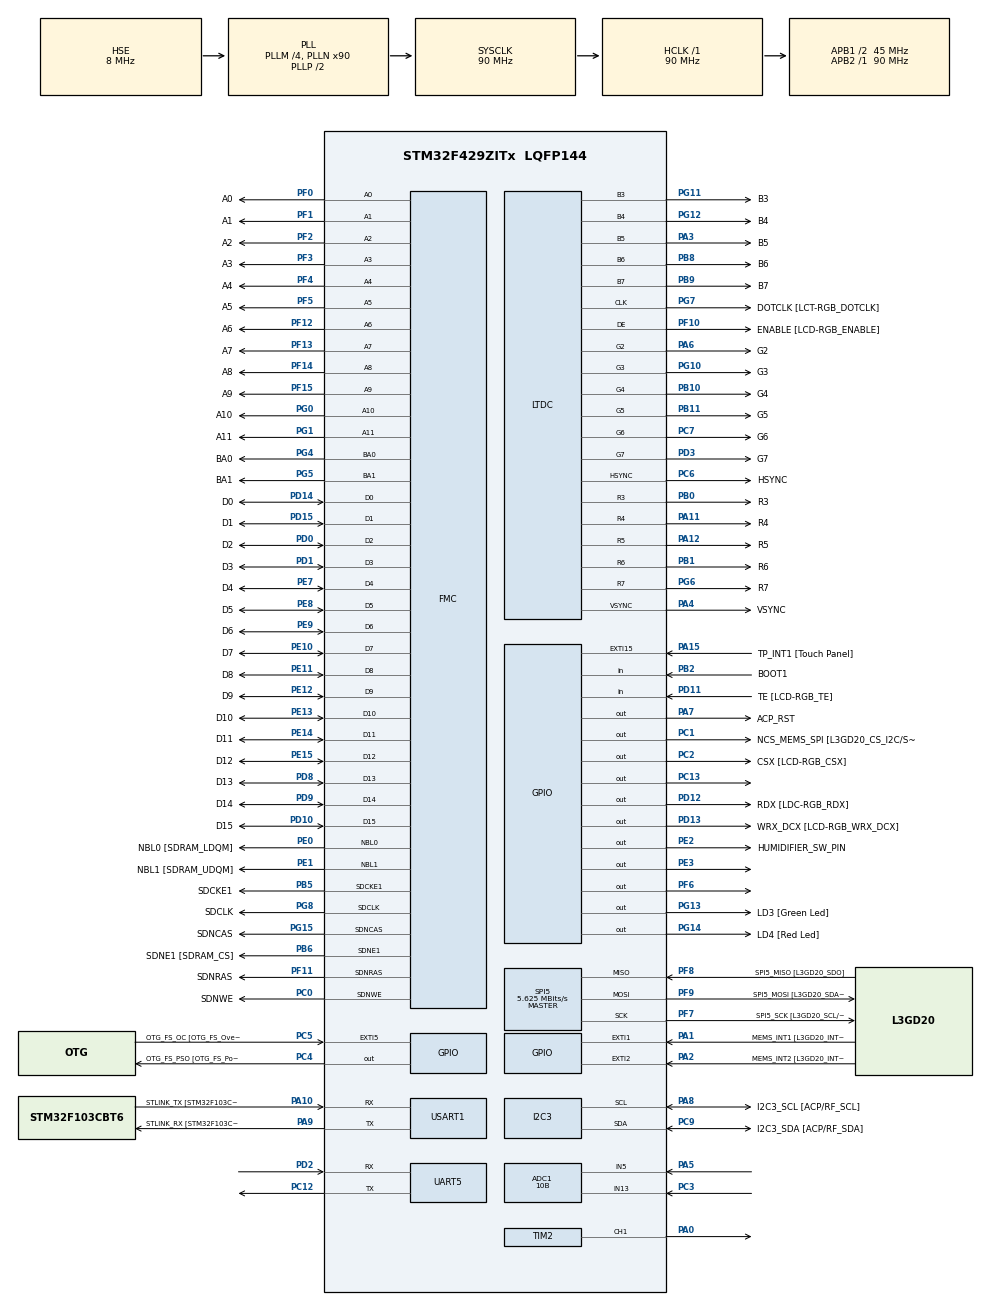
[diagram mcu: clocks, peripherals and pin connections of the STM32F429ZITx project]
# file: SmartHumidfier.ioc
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PF5.GPIO_PuPd=GPIO_NOPULL
FREERTOS.Queues01=envQueue,16,ENV_MSG,0,Dynamic,NULL,NULL
PD12.GPIO_Label=RDX [LDC-RGB_RDX]
FMC.SDClockPeriod2=FMC_SDRAM_CLOCK_PERIOD_2
FMC.SDClockPeriod1=FMC_SDRAM_CLOCK_PERIOD_2
SH.FMC_A0.0=FMC_A0,12b-sda1
PB10.GPIO_PuPd=GPIO_NOPULL
NVIC.TIM6_DAC_IRQn=true\:0\:0\:false\:false\:true\:false\:false\:true
PG8.Signal=FMC_SDCLK
FREERTOS.Events01=eventFlag,Dynamic,NULL
PG0.Signal=FMC_A10
PA3.GPIO_PuPd=GPIO_NOPULL
PE10.GPIO_PuPd=GPIO_NOPULL
PD10.GPIO_PuPd=GPIO_NOPULL
SH.FMC_D5_DA5.0=FMC_D5,sd-16b-d1
PF10.GPIO_PuPd=GPIO_NOPULL
PG10.GPIO_PuPd=GPIO_NOPULL
PA6.GPIO_Mode=GPIO_MODE_AF_PP
SH.FMC_D9_DA9.0=FMC_D9,sd-16b-d1
PB2/BOOT1.GPIO_Mode=GPIO_MODE_INPUT
PG13.GPIO_Mode=GPIO_MODE_OUTPUT_PP
PE13.GPIO_Mode=GPIO_MODE_AF_PP
PF13.GPIO_Mode=GPIO_MODE_AF_PP
PG15.GPIO_Label=SDNCAS
PA4.Mode=RGB565
PF7.Signal=SPI5_SCK
PD13.GPIO_Mode=GPIO_MODE_OUTPUT_PP
NVIC.DMA2D_IRQn=true\:5\:0\:true\:false\:true\:true\:true\:true
SH.FMC_SDNWE.0=FMC_SDNWE,12b-sda1
PA15.GPIO_ModeDefaultEXTI=GPIO_MODE_EVT_RISING
SH.FMC_D11_DA11.0=FMC_D11,sd-16b-d1
PG7.GPIO_Mode=GPIO_MODE_AF_PP
RCC.APB2TimFreq_Value=90000000
PC4.GPIO_Mode=GPIO_MODE_OUTPUT_PP
PB6.Signal=FMC_SDNE1
PC7.Signal=LTDC_G6
PD0.Signal=FMC_D2_DA2
PD8.Signal=FMC_D13_DA13
PE1.Signal=FMC_NBL1
ADC1.ScanConvMode=ENABLE
PF1.GPIO_Label=A1
PC1.GPIO_PuPd=GPIO_NOPULL
PD1.GPIO_Label=D3
FMC.SelfRefreshTime1=4
PF12.GPIO_Label=A6
LTDC.PixelFormat_L0=LTDC_PIXEL_FORMAT_RGB565
PC4.GPIO_Label=OTG_FS_PSO [OTG_FS_PowerSwitchOn]
PB1.GPIO_Speed=GPIO_SPEED_FREQ_LOW
PE9.Signal=FMC_D6_DA6
PD1.GPIO_Speed=GPIO_SPEED_FREQ_VERY_HIGH
SH.FMC_A2.0=FMC_A2,12b-sda1
PB1.GPIO_Label=R6
PG4.GPIO_Label=BA0
PC9.Mode=I2C
PD14.GPIO_PuPd=GPIO_NOPULL
PA8.Signal=I2C3_SCL
SH.FMC_D1_DA1.0=FMC_D1,sd-16b-d1
PF1.GPIO_Speed=GPIO_SPEED_FREQ_VERY_HIGH
PF1.GPIO_Mode=GPIO_MODE_AF_PP
LTDC.HSync=10
PF14.GPIO_PuPd=GPIO_NOPULL
PG0.GPIO_PuPd=GPIO_NOPULL
PE9.GPIO_Mode=GPIO_MODE_AF_PP
Mcu.Package=LQFP144
PB9.Signal=LTDC_B7
TIM2.Prescaler=900-1
PB1.Signal=LTDC_R6
NVIC.TimeBase=TIM6_DAC_IRQn
PD12.Signal=GPIO_Output
NVIC.TimeBaseIP=TIM6
PA10.Signal=USART1_RX
PB9.GPIO_PuPd=GPIO_NOPULL
PE12.GPIO_Label=D9
FMC.WriteRecoveryTime1=3
PE12.GPIO_Speed=GPIO_SPEED_FREQ_VERY_HIGH
PB5.GPIO_Speed=GPIO_SPEED_FREQ_VERY_HIGH
SPI5.CalculateBaudRate=5.625 MBits/s
PE8.GPIO_Speed=GPIO_SPEED_FREQ_VERY_HIGH
PG8.GPIO_Speed=GPIO_SPEED_FREQ_VERY_HIGH
LTDC.VSync=2
PF5.GPIO_Speed=GPIO_SPEED_FREQ_VERY_HIGH
RCC.APB1TimFreq_Value=90000000
FMC.RowCycleDelay2=7
PF10.Mode=RGB565
FMC.RowCycleDelay1=7
PD3.GPIO_PuPd=GPIO_NOPULL
PF9.GPIO_PuPd=GPIO_NOPULL
PA4.GPIO_Label=VSYNC
PA8.GPIO_Speed=GPIO_SPEED_FREQ_LOW
PD15.Signal=FMC_D1_DA1
PG12.Signal=LTDC_B4
PB5.GPIO_Mode=GPIO_MODE_AF_PP
SH.FMC_A4.0=FMC_A4,12b-sda1
FREERTOS.Tasks01=defaultTask,8,4096,StartDefaultTask,Default,NULL,Dynamic,NULL,NULL;lcdTask,24,512,_TouchGFX_Task,Default,NULL,Dynamic,NULL,NULL;eventHandlerTas,40,2048,___eventHandler,Default,NULL,Dynamic,NULL,NULL;event_loop_task,32,512,_eventLoopTask,Default,NULL,Dynamic,NULL,NULL
PF4.GPIO_Mode=GPIO_MODE_AF_PP
PG5.Signal=FMC_A15_BA1
SH.FMC_D10_DA10.0=FMC_D10,sd-16b-d1
PC13.Signal=GPIO_Output
PB6.GPIO_PuPd=GPIO_NOPULL
PD3.Signal=LTDC_G7
PC2.Signal=GPIO_Output
PF5.GPIO_Mode=GPIO_MODE_AF_PP
PG8.GPIO_PuPd=GPIO_NOPULL
PF8.GPIO_Label=SPI5_MISO [L3GD20_SDO]
LTDC.ImageWidth_L0=240
PD10.Signal=FMC_D15_DA15
PA3.Mode=RGB565
PB8.GPIO_Label=B6
PB10.GPIO_Mode=GPIO_MODE_AF_PP
PA8.GPIO_Label=I2C3_SCL [ACP/RF_SCL]
PE8.GPIO_Label=D5
PB1.GPIO_Mode=GPIO_MODE_AF_PP
PC5.GPIO_ModeDefaultEXTI=GPIO_MODE_EVT_RISING
PG10.GPIO_Mode=GPIO_MODE_AF_PP
PA5.Signal=ADCx_IN5
PC12.Mode=Asynchronous
PF10.GPIO_Mode=GPIO_MODE_AF_PP
PE1.GPIO_Label=NBL1 [SDRAM_UDQM]
PF15.GPIO_Speed=GPIO_SPEED_FREQ_VERY_HIGH
PF13.GPIO_PuPd=GPIO_NOPULL
FMC.ReadBurst1=FMC_SDRAM_RBURST_DISABLE
SH.FMC_A6.0=FMC_A6,12b-sda1
PE14.Signal=FMC_D11_DA11
PF12.GPIO_Speed=GPIO_SPEED_FREQ_VERY_HIGH
PG7.GPIO_Label=DOTCLK [LCT-RGB_DOTCLK]
PF4.GPIO_Label=A4
PA1.GPIO_Label=MEMS_INT1 [L3GD20_INT1]
PC9.GPIO_PuPd=GPIO_NOPULL
PC1.GPIO_Speed=GPIO_SPEED_FREQ_LOW
PF13.Signal=FMC_A7
TIM2.Period=65535
PG14.GPIO_PuPd=GPIO_NOPULL
PG1.GPIO_Speed=GPIO_SPEED_FREQ_VERY_HIGH
PC7.GPIO_Label=G6
ADC1.master=1
PB5.GPIO_PuPd=GPIO_NOPULL
ProjectManager.HeapSize=0x200
PB1.Mode=RGB565
PD0.GPIO_PuPd=GPIO_NOPULL
FREERTOS.configUSE_RECURSIVE_MUTEXES=1
PG12.GPIO_Speed=GPIO_SPEED_FREQ_LOW
PD8.GPIO_Speed=GPIO_SPEED_FREQ_VERY_HIGH
NVIC.PriorityGroup=NVIC_PRIORITYGROUP_4
PF0.GPIO_Label=A0
PE15.GPIO_Speed=GPIO_SPEED_FREQ_VERY_HIGH
PE3.Signal=GPIO_Output
PF4.Signal=FMC_A4
PD2.Signal=UART5_RX
PD14.GPIO_Mode=GPIO_MODE_AF_PP
PG5.GPIO_Speed=GPIO_SPEED_FREQ_VERY_HIGH
Mcu.Family=STM32F4
LTDC.BlendingFactor1_L0=LTDC_BLENDING_FACTOR1_CA
PA6.Mode=RGB565
SH.FMC_A8.0=FMC_A8,12b-sda1
FREERTOS.BinarySemaphores01=sensorSem,Dynamic,NULL
TIM2.OCFastMode_PWM-PWM\ Generation1\ CH1=TIM_OCFAST_ENABLE
ADC1.ContinuousConvMode=ENABLE
SH.FMC_D14_DA14.0=FMC_D14,sd-16b-d1
PE11.GPIO_Label=D8
PA7.GPIO_Mode=GPIO_MODE_OUTPUT_PP
PD9.GPIO_Speed=GPIO_SPEED_FREQ_VERY_HIGH
PD0.GPIO_Label=D2
PA11.Mode=RGB565
PF9.GPIO_Speed=GPIO_SPEED_FREQ_LOW
PC2.GPIO_Speed=GPIO_SPEED_FREQ_LOW
SH.FMC_A14_BA0.0=FMC_BA0,FourSdramBanks1
SH.FMC_A11.0=FMC_A11,12b-sda1
PD8.GPIO_PuPd=GPIO_NOPULL
PG5.GPIO_Label=BA1
PG11.Signal=LTDC_B3
PG15.Signal=FMC_SDNCAS
PD13.Signal=GPIO_Output
PA15.GPIO_Label=TP_INT1 [Touch Panel]
PE11.GPIO_PuPd=GPIO_NOPULL
PF11.GPIO_PuPd=GPIO_NOPULL
PB1.GPIO_PuPd=GPIO_NOPULL
ADC1.Resolution=ADC_RESOLUTION_10B
PF13.GPIO_Speed=GPIO_SPEED_FREQ_VERY_HIGH
SH.FMC_NBL1.0=FMC_NBL1,Sd2ByteEnable1
LTDC.WindowX1_L0=240
PG5.GPIO_PuPd=GPIO_NOPULL
RCC.HSE_VALUE=8000000
FREERTOS.configUSE_TIMERS=1
PA4.GPIO_PuPd=GPIO_NOPULL
FMC.ExitSelfRefreshDelay1=7
PF7.GPIO_Mode=GPIO_MODE_AF_PP
PE13.GPIO_PuPd=GPIO_NOPULL
PA4.GPIO_Speed=GPIO_SPEED_FREQ_LOW
FREERTOS.configENABLE_BACKWARD_COMPATIBILITY=1
PG11.GPIO_Speed=GPIO_SPEED_FREQ_LOW
PH1/OSC_OUT.GPIO_Label=PH1-OSC_OUT
PC4.GPIO_Speed=GPIO_SPEED_FREQ_LOW
PA6.GPIO_PuPd=GPIO_NOPULL
PF9.Mode=Full_Duplex_Master
PF7.GPIO_Speed=GPIO_SPEED_FREQ_LOW
PF8.GPIO_PuPd=GPIO_NOPULL
PA14.Mode=Serial_Wire
PB2/BOOT1.GPIO_PuPd=GPIO_NOPULL
PF11.Signal=FMC_SDNRAS
PB5.Mode=SdramChipSelect2_1
PC7.GPIO_Mode=GPIO_MODE_AF_PP
PG7.GPIO_PuPd=GPIO_NOPULL
TIM2.Channel-PWM\ Generation1\ CH1=TIM_CHANNEL_1
PD10.GPIO_Speed=GPIO_SPEED_FREQ_VERY_HIGH
PG4.GPIO_Mode=GPIO_MODE_AF_PP
PD13.GPIO_Label=WRX_DCX [LCD-RGB_WRX_DCX]
PA6.Signal=LTDC_G2
PB0.GPIO_Mode=GPIO_MODE_AF_PP
PG1.GPIO_PuPd=GPIO_NOPULL
PA15.Signal=GPXTI15
PF8.Signal=SPI5_MISO
PG0.GPIO_Label=A10
PB5.GPIO_Label=SDCKE1
PD0.GPIO_Mode=GPIO_MODE_AF_PP
PG14.GPIO_Mode=GPIO_MODE_OUTPUT_PP
PG11.GPIO_Label=B3
PC5.Signal=GPXTI5
PD3.GPIO_Label=G7
PE14.GPIO_Mode=GPIO_MODE_AF_PP
PE7.Signal=FMC_D4_DA4
ADC1.Rank-6\#ChannelRegularConversion=1
PF3.GPIO_Label=A3
PA1.GPIO_ModeDefaultEXTI=GPIO_MODE_EVT_RISING
PE2.GPIO_Label=HUMIDIFIER_SW_PIN
PA12.GPIO_Speed=GPIO_SPEED_FREQ_LOW
STMicroelectronics.X-CUBE-TOUCHGFX.4.16.1.tgfx_vsync=vsync_ltdc
PA3.Signal=LTDC_B5
PE0.GPIO_PuPd=GPIO_NOPULL
PG1.GPIO_Mode=GPIO_MODE_AF_PP
NVIC.LTDC_IRQn=true\:5\:0\:true\:false\:true\:true\:true\:true
SH.ADCx_IN13.0=ADC1_IN13,IN13
LTDC.VFP=4
PD15.GPIO_Label=D1
LTDC.WindowY1_L0=320
PG7.Signal=LTDC_CLK
PA10.Mode=Asynchronous
PC9.GPIO_Label=I2C3_SDA [ACP/RF_SDA]
PF10.GPIO_Speed=GPIO_SPEED_FREQ_LOW
PE14.GPIO_Label=D11
PD9.Signal=FMC_D14_DA14
SPI5.Mode=SPI_MODE_MASTER
PA12.GPIO_Label=R5
PD8.GPIO_Label=D13
PB0.GPIO_Speed=GPIO_SPEED_FREQ_LOW
PG8.GPIO_Label=SDCLK
PA13.Signal=SYS_JTMS-SWDIO
FREERTOS.configUSE_IDLE_HOOK=1
PA9.Mode=Asynchronous
PB2/BOOT1.Signal=GPIO_Input
PF6.Signal=GPIO_Output
PB10.GPIO_Label=G4
PC9.GPIO_Mode=GPIO_MODE_AF_OD
SH.FMC_D13_DA13.0=FMC_D13,sd-16b-d1
PA3.GPIO_Mode=GPIO_MODE_AF_PP
PG0.GPIO_Speed=GPIO_SPEED_FREQ_VERY_HIGH
PB9.Mode=RGB565
PF9.GPIO_Label=SPI5_MOSI [L3GD20_SDA/SDI/SDO]
PD10.GPIO_Label=D15
PA1.Signal=GPXTI1
PA7.GPIO_PuPd=GPIO_NOPULL
PD2.Mode=Asynchronous
PE10.GPIO_Mode=GPIO_MODE_AF_PP
board=STM32F429I-DISC1
PD13.GPIO_Speed=GPIO_SPEED_FREQ_LOW
PG12.Mode=RGB565
PC7.GPIO_Speed=GPIO_SPEED_FREQ_LOW
RCC.VCOOutputFreq_Value=180000000
PA4.GPIO_Mode=GPIO_MODE_AF_PP
PF4.GPIO_Speed=GPIO_SPEED_FREQ_VERY_HIGH
PC1.GPIO_Label=NCS_MEMS_SPI [L3GD20_CS_I2C/SPI]
PE11.GPIO_Mode=GPIO_MODE_AF_PP
SH.FMC_D12_DA12.0=FMC_D12,sd-16b-d1
PF15.GPIO_Label=A9
PE14.GPIO_PuPd=GPIO_NOPULL
PF1.Signal=FMC_A1
ADC1.NbrOfConversion=1
PF8.GPIO_Mode=GPIO_MODE_AF_PP
PE0.Signal=FMC_NBL0
PE7.GPIO_Label=D4
PE12.Signal=FMC_D9_DA9
PE12.GPIO_Mode=GPIO_MODE_AF_PP
RCC.48MHZClocksFreq_Value=60000000
RCC.SYSCLKFreq_VALUE=90000000
PE15.GPIO_PuPd=GPIO_NOPULL
PG4.GPIO_PuPd=GPIO_NOPULL
PD3.GPIO_Mode=GPIO_MODE_AF_PP
RCC.HSI_VALUE=16000000
PA8.GPIO_PuPd=GPIO_NOPULL
PA2.GPIO_ModeDefaultEXTI=GPIO_MODE_EVT_RISING
PH0/OSC_IN.GPIO_Label=PH0-OSC_IN
PF9.GPIO_Mode=GPIO_MODE_AF_PP
RCC.PLLQ=3
RCC.PLLM=4
RCC.PLLN=90
PG0.GPIO_Mode=GPIO_MODE_AF_PP
PB8.GPIO_Speed=GPIO_SPEED_FREQ_LOW
PG14.GPIO_Speed=GPIO_SPEED_FREQ_LOW
VP_CRC_VS_CRC.Mode=CRC_Activate
LTDC.ImageHeight_L0=320
PB0.GPIO_PuPd=GPIO_NOPULL
PA3.GPIO_Label=B5
PA11.GPIO_Speed=GPIO_SPEED_FREQ_LOW
PF15.GPIO_Mode=GPIO_MODE_AF_PP
SH.FMC_D7_DA7.0=FMC_D7,sd-16b-d1
PE15.GPIO_Mode=GPIO_MODE_AF_PP
PD1.GPIO_Mode=GPIO_MODE_AF_PP
PD15.GPIO_Mode=GPIO_MODE_AF_PP
VP_SYS_VS_tim6.Mode=TIM6
PE14.GPIO_Speed=GPIO_SPEED_FREQ_VERY_HIGH
FMC.RCDDelay1=2
PB10.Mode=RGB565
PA8.GPIO_Mode=GPIO_MODE_AF_OD
PG4.Signal=FMC_A14_BA0
ADC1.SamplingTime-6\#ChannelRegularConversion=ADC_SAMPLETIME_15CYCLES
PC12.Signal=UART5_TX
PG6.GPIO_Label=R7
PA14.GPIO_Label=SWCLK
PE8.GPIO_PuPd=GPIO_NOPULL
FMC.LoadToActiveDelay1=2
PC6.GPIO_Label=HSYNC
PA6.GPIO_Label=G2
PB6.GPIO_Label=SDNE1 [SDRAM_CS]
PA3.GPIO_Speed=GPIO_SPEED_FREQ_LOW
PD3.GPIO_Speed=GPIO_SPEED_FREQ_LOW
PG6.Mode=RGB565
PG13.Signal=GPIO_Output
RCC.SYSCLKSource=RCC_SYSCLKSOURCE_PLLCLK
PG15.GPIO_Mode=GPIO_MODE_AF_PP
PB11.GPIO_Speed=GPIO_SPEED_FREQ_LOW
SH.FMC_A15_BA1.0=FMC_BA1,FourSdramBanks1
PD14.GPIO_Speed=GPIO_SPEED_FREQ_VERY_HIGH
PB2/BOOT1.GPIO_Label=BOOT1
PH1/OSC_OUT.Signal=RCC_OSC_OUT
PB6.Mode=SdramChipSelect2_1
PC3.Signal=ADCx_IN13
PA1.GPIO_PuPd=GPIO_NOPULL
PF10.GPIO_Label=ENABLE [LCD-RGB_ENABLE]
PF14.GPIO_Speed=GPIO_SPEED_FREQ_VERY_HIGH
PG6.GPIO_PuPd=GPIO_NOPULL
PF11.GPIO_Mode=GPIO_MODE_AF_PP
STMicroelectronics.X-CUBE-TOUCHGFX.4.16.1.tgfx_display_interface=disp_ltdc
PD11.GPIO_Mode=GPIO_MODE_INPUT
PE2.Signal=GPIO_Output
PF8.Mode=Full_Duplex_Master
PF3.Signal=FMC_A3
PD3.Mode=RGB565
PE10.Signal=FMC_D7_DA7
VP_TIM1_VS_ClockSourceINT.Mode=Internal
STMicroelectronics.X-CUBE-TOUCHGFX.4.16.1.ApplicationCcGraphicsJjApplication=TouchGFXOoGenerator
PF3.GPIO_Speed=GPIO_SPEED_FREQ_VERY_HIGH
PF3.GPIO_PuPd=GPIO_NOPULL
PC6.GPIO_PuPd=GPIO_NOPULL
SH.FMC_A1.0=FMC_A1,12b-sda1
SH.FMC_SDCLK.0=FMC_SDCLK,12b-sda1
PC2.GPIO_Mode=GPIO_MODE_OUTPUT_PP
PG12.GPIO_PuPd=GPIO_NOPULL
PF14.Signal=FMC_A8
VP_DMA2D_VS_DMA2D.Mode=DMA2D_Activate
PA6.GPIO_Speed=GPIO_SPEED_FREQ_LOW
PB11.GPIO_Mode=GPIO_MODE_AF_PP
PA12.GPIO_PuPd=GPIO_NOPULL
PE10.GPIO_Label=D7
PD9.GPIO_PuPd=GPIO_NOPULL
PC6.GPIO_Speed=GPIO_SPEED_FREQ_LOW
SH.FMC_D3_DA3.0=FMC_D3,sd-16b-d1
SPI5.VirtualType=VM_MASTER
PG6.GPIO_Speed=GPIO_SPEED_FREQ_LOW
PE12.GPIO_PuPd=GPIO_NOPULL
PD8.GPIO_Mode=GPIO_MODE_AF_PP
VP_STMicroelectronics.X-CUBE-TOUCHGFX_VS_GraphicsJjApplication_4.16.1.Mode=GraphicsJjApplication
PD9.GPIO_Label=D14
STMicroelectronics.X-CUBE-TOUCHGFX.4.16.1.tgfx_address1=0xD0000000
PE11.GPIO_Speed=GPIO_SPEED_FREQ_VERY_HIGH
PA9.GPIO_Label=STLINK_RX [STM32F103CBT6_PA3]
FREERTOS.configCHECK_FOR_STACK_OVERFLOW=2
PD9.GPIO_Mode=GPIO_MODE_AF_PP
PB8.GPIO_PuPd=GPIO_NOPULL
PC6.Signal=LTDC_HSYNC
PB11.GPIO_Label=G5
PD1.Signal=FMC_D3_DA3
PA11.GPIO_Label=R4
PE1.GPIO_PuPd=GPIO_NOPULL
PF14.GPIO_Label=A8
PD1.GPIO_PuPd=GPIO_NOPULL
UART5.VirtualMode=Asynchronous
PC0.Signal=FMC_SDNWE
RCC.APB1CLKDivider=RCC_HCLK_DIV2
PF13.GPIO_Label=A7
PG13.GPIO_Label=LD3 [Green Led]
PD0.GPIO_Speed=GPIO_SPEED_FREQ_VERY_HIGH
PG10.Signal=LTDC_G3
PE0.GPIO_Speed=GPIO_SPEED_FREQ_VERY_HIGH
PF11.GPIO_Speed=GPIO_SPEED_FREQ_VERY_HIGH
SH.FMC_A3.0=FMC_A3,12b-sda1
FMC.CASLatency1=FMC_SDRAM_CAS_LATENCY_3
PF2.GPIO_Mode=GPIO_MODE_AF_PP
PB11.Mode=RGB565
SH.FMC_D15_DA15.0=FMC_D15,sd-16b-d1
PC6.Mode=RGB565
PA9.Signal=USART1_TX
PC7.GPIO_PuPd=GPIO_NOPULL
PE9.GPIO_Label=D6
PB10.Signal=LTDC_G4
PA7.GPIO_Speed=GPIO_SPEED_FREQ_LOW
PE7.GPIO_Speed=GPIO_SPEED_FREQ_VERY_HIGH
PE15.Signal=FMC_D12_DA12
PG11.GPIO_Mode=GPIO_MODE_AF_PP
PE8.Signal=FMC_D5_DA5
PG5.GPIO_Mode=GPIO_MODE_AF_PP
PC6.GPIO_Mode=GPIO_MODE_AF_PP
ADC1.DMAContinuousRequests=DISABLE
PA13.Mode=Serial_Wire
PG14.GPIO_Label=LD4 [Red Led]
SH.FMC_SDNCAS.0=FMC_SDNCAS,12b-sda1
PG12.GPIO_Mode=GPIO_MODE_AF_PP
PF7.GPIO_PuPd=GPIO_NOPULL
PA4.Signal=LTDC_VSYNC
PB5.Signal=FMC_SDCKE1
PE13.GPIO_Label=D10
FREERTOS.configUSE_COUNTING_SEMAPHORES=1
PE3.GPIO_ModeDefaultOutputPP=GPIO_MODE_OUTPUT_PP
PD11.Signal=GPIO_Input
USART1.VirtualMode=VM_ASYNC
SH.FMC_A5.0=FMC_A5,12b-sda1
PG11.Mode=RGB565
LTDC.Alpha_L0=255
PA11.Signal=LTDC_R4
SH.S_TIM2_CH1_ETR.0=TIM2_CH1,PWM Generation1 CH1
PF9.Signal=SPI5_MOSI
FREERTOS.Timers01=updateSensorTimer,CallbackUpdateSensor,osTimerPeriodic,Default,NULL,Dynamic,NULL
SH.ADCx_IN5.0=ADC1_IN5,IN5
PC9.GPIO_Speed=GPIO_SPEED_FREQ_LOW
PB8.Mode=RGB565
PF12.GPIO_PuPd=GPIO_NOPULL
TIM2.AutoReloadPreload=TIM_AUTORELOAD_PRELOAD_ENABLE
PA8.Mode=I2C
PB6.GPIO_Speed=GPIO_SPEED_FREQ_VERY_HIGH
PG6.GPIO_Mode=GPIO_MODE_AF_PP
PB0.Signal=LTDC_R3
PE0.GPIO_Mode=GPIO_MODE_AF_PP
PC1.Signal=GPIO_Output
PF3.GPIO_Mode=GPIO_MODE_AF_PP
PG10.GPIO_Label=G3
PG15.GPIO_PuPd=GPIO_NOPULL
PA2.GPIO_PuPd=GPIO_NOPULL
PE7.GPIO_PuPd=GPIO_NOPULL
RCC.CortexFreq_Value=90000000
PG6.Signal=LTDC_R7
PB10.GPIO_Speed=GPIO_SPEED_FREQ_LOW
PB6.GPIO_Mode=GPIO_MODE_AF_PP
LTDC.HBP=20
PD15.GPIO_Speed=GPIO_SPEED_FREQ_VERY_HIGH
PF4.GPIO_PuPd=GPIO_NOPULL
SH.FMC_NBL0.0=FMC_NBL0,Sd2ByteEnable1
SH.FMC_D6_DA6.0=FMC_D6,sd-16b-d1
PC0.GPIO_Label=SDNWE
PE9.GPIO_Speed=GPIO_SPEED_FREQ_VERY_HIGH
PA0/WKUP.Signal=S_TIM2_CH1_ETR
PB0.GPIO_Label=R3
PA11.GPIO_PuPd=GPIO_NOPULL
PB11.GPIO_PuPd=GPIO_NOPULL
PB11.Signal=LTDC_G5
PG8.GPIO_Mode=GPIO_MODE_AF_PP
STMicroelectronics.X-CUBE-TOUCHGFX.4.16.1.tgfx_location=By Address
PF2.GPIO_Speed=GPIO_SPEED_FREQ_VERY_HIGH
ProjectManager.StackSize=0x400
VP_FREERTOS_VS_CMSIS_V2.Mode=CMSIS_V2
NVIC.UART5_IRQn=true\:5\:0\:false\:false\:true\:true\:true\:true
PD11.GPIO_PuPd=GPIO_NOPULL
SH.FMC_A7.0=FMC_A7,12b-sda1
PA12.Signal=LTDC_R5
PE1.GPIO_Mode=GPIO_MODE_AF_PP
PH0/OSC_IN.Mode=HSE-External-Oscillator
PG11.GPIO_PuPd=GPIO_NOPULL
PD11.GPIO_Label=TE [LCD-RGB_TE]
RCC.HCLKFreq_Value=90000000
PF11.GPIO_Label=SDNRAS
PF2.GPIO_PuPd=GPIO_NOPULL
PF12.Signal=FMC_A6
FREERTOS.configUSE_MALLOC_FAILED_HOOK=1
SH.FMC_A10.0=FMC_A10,12b-sda1
RCC.AHBFreq_Value=90000000
PC1.GPIO_Mode=GPIO_MODE_OUTPUT_PP
SH.FMC_D8_DA8.0=FMC_D8,sd-16b-d1
FMC.RPDelay2=2
FMC.RPDelay1=2
PG13.GPIO_PuPd=GPIO_NOPULL
SH.FMC_D2_DA2.0=FMC_D2,sd-16b-d1
ADC1.Channel-6\#ChannelRegularConversion=ADC_CHANNEL_13
PE13.Signal=FMC_D10_DA10
PF7.GPIO_Label=SPI5_SCK [L3GD20_SCL/SPC]
PG4.GPIO_Speed=GPIO_SPEED_FREQ_VERY_HIGH
PA10.GPIO_Label=STLINK_TX [STM32F103CBT6_PA2]
LTDC.HFP=10
LTDC.BlendingFactor2_L0=LTDC_BLENDING_FACTOR2_CA
FMC.ReadPipeDelay1=FMC_SDRAM_RPIPE_DELAY_1
FMC.ReadPipeDelay2=FMC_SDRAM_RPIPE_DELAY_1
PE10.GPIO_Speed=GPIO_SPEED_FREQ_VERY_HIGH
SH.FMC_SDNRAS.0=FMC_SDNRAS,12b-sda1
DMA2D.ColorMode=DMA2D_OUTPUT_RGB565
LTDC.ActiveW=240
PH1/OSC_OUT.Mode=HSE-External-Oscillator
FREERTOS.configTOTAL_HEAP_SIZE=32768
PF12.GPIO_Mode=GPIO_MODE_AF_PP
PD12.GPIO_Mode=GPIO_MODE_OUTPUT_PP
SPI5.BaudRatePrescaler=SPI_BAUDRATEPRESCALER_16
SH.FMC_D0_DA0.0=FMC_D0,sd-16b-d1
PG15.GPIO_Speed=GPIO_SPEED_FREQ_VERY_HIGH
PF15.GPIO_PuPd=GPIO_NOPULL
PA2.GPIO_Label=MEMS_INT2 [L3GD20_INT2]
PD15.GPIO_PuPd=GPIO_NOPULL
PF5.GPIO_Label=A5
SH.FMC_A9.0=FMC_A9,12b-sda1
SH.FMC_D4_DA4.0=FMC_D4,sd-16b-d1
PE8.GPIO_Mode=GPIO_MODE_AF_PP
PE0.GPIO_Label=NBL0 [SDRAM_LDQM]
RCC.PLLSAIN=56
PF5.Signal=FMC_A5
RCC.PLLSAIR=7
PB9.GPIO_Speed=GPIO_SPEED_FREQ_LOW
PG13.GPIO_Speed=GPIO_SPEED_FREQ_LOW
PF0.Signal=FMC_A0
PC0.GPIO_PuPd=GPIO_NOPULL
PC2.GPIO_Label=CSX [LCD-RGB_CSX]
PF0.GPIO_Mode=GPIO_MODE_AF_PP
RCC.PLLSourceVirtual=RCC_PLLSOURCE_HSE
LTDC.FBStartAdress_L0=0xD0000000
PD12.GPIO_Speed=GPIO_SPEED_FREQ_LOW
TIM2.CounterMode=TIM_COUNTERMODE_DOWN
PB9.GPIO_Label=B7
PC4.GPIO_PuPd=GPIO_NOPULL
PG1.Signal=FMC_A11
PC4.Signal=GPIO_Output
PG10.Mode=RGB565
FREERTOS.configUSE_APPLICATION_TASK_TAG=1
PG10.GPIO_Speed=GPIO_SPEED_FREQ_LOW
PF0.GPIO_Speed=GPIO_SPEED_FREQ_VERY_HIGH
PD10.GPIO_Mode=GPIO_MODE_AF_PP
PF7.Mode=Full_Duplex_Master
PC0.GPIO_Speed=GPIO_SPEED_FREQ_VERY_HIGH
PE15.GPIO_Label=D12
STMicroelectronics.X-CUBE-TOUCHGFX.4.16.1.tgfx_hardware_accelerator=dma_2d
ProjectManager.TargetToolchain=STM32CubeIDE
FREERTOS.configTIMER_TASK_STACK_DEPTH=1024
LTDC.ActiveH=320
PF2.Signal=FMC_A2
PE11.Signal=FMC_D8_DA8
PG7.Mode=RGB565
RCC.LSE_VALUE=32768
PE7.GPIO_Mode=GPIO_MODE_AF_PP
PG14.Signal=GPIO_Output
PB0.Mode=RGB565
PG1.GPIO_Label=A11
PB9.GPIO_Mode=GPIO_MODE_AF_PP
PA12.GPIO_Mode=GPIO_MODE_AF_PP
PH0/OSC_IN.Signal=RCC_OSC_IN
PG7.GPIO_Speed=GPIO_SPEED_FREQ_LOW
RCC.APB2Freq_Value=90000000
PC0.GPIO_Mode=GPIO_MODE_AF_PP
LTDC.Layers=0
VP_TIM2_VS_ClockSourceINT.Mode=Internal
PF10.Signal=LTDC_DE
PE1.GPIO_Speed=GPIO_SPEED_FREQ_VERY_HIGH
PF1.GPIO_PuPd=GPIO_NOPULL
PD13.GPIO_PuPd=GPIO_NOPULL
PF15.Signal=FMC_A9
PD14.GPIO_Label=D0
PC2.GPIO_PuPd=GPIO_NOPULL
Mcu.Name=STM32F429ZITx
PA2.Signal=GPXTI2
PA13.GPIO_Label=SWDIO
PD14.Signal=FMC_D0_DA0
PF0.GPIO_PuPd=GPIO_NOPULL
PA7.GPIO_Label=ACP_RST
PA12.Mode=RGB565
PC5.GPIO_Label=OTG_FS_OC [OTG_FS_OverCurrent]
PA14.Signal=SYS_JTCK-SWCLK
PG12.GPIO_Label=B4
ADC1.NbrOfConversionFlag=1
PF8.GPIO_Speed=GPIO_SPEED_FREQ_LOW
PA15.GPIO_PuPd=GPIO_NOPULL
PE13.GPIO_Speed=GPIO_SPEED_FREQ_VERY_HIGH
PB8.Signal=LTDC_B6
PF14.GPIO_Mode=GPIO_MODE_AF_PP
PC9.Signal=I2C3_SDA
PC7.Mode=RGB565
PA11.GPIO_Mode=GPIO_MODE_AF_PP
PB8.GPIO_Mode=GPIO_MODE_AF_PP
RCC.APB1Freq_Value=45000000
PD12.GPIO_PuPd=GPIO_NOPULL
SPI5.Direction=SPI_DIRECTION_2LINES
PA7.Signal=GPIO_Output
PE9.GPIO_PuPd=GPIO_NOPULL
PF2.GPIO_Label=A2

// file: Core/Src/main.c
/* USER CODE BEGIN Header */
/**
  ******************************************************************************
  * @file           : main.c
  * @brief          : Main program body
  ******************************************************************************
  * @attention
  *
  * <h2><center>&copy; Copyright (c) 2022 STMicroelectronics.
  * All rights reserved.</center></h2>
  *
  * This software component is licensed by ST under Ultimate Liberty license
  * SLA0044, the "License"; You may not use this file except in compliance with
  * the License. You may obtain a copy of the License at:
  *                             www.st.com/SLA0044
  *
  ******************************************************************************
  */
/* USER CODE END Header */
#include "main.h"
#include "cmsis_os.h"
#include "adc.h"
#include "crc.h"
#include "dma2d.h"
#include "i2c.h"
#include "ltdc.h"
#include "spi.h"
#include "tim.h"
#include "usart.h"
#include "gpio.h"
#include "fmc.h"
#include "app_touchgfx.h"

/* USER CODE BEGIN Includes */
#include "common.h"
#include "mqtt.h"
#include "dwt_stm32_delay.h"
/* USER CODE END Includes */

void SystemClock_Config(void);
void MX_FREERTOS_Init(void);

int main(void)
{

  /* MCU Configuration--------------------------------------------------------*/

  /* Reset of all peripherals, Initializes the Flash interface and the Systick. */
HAL_Init();

  /* Configure the system clock */
  SystemClock_Config();

  /* Initialize all configured peripherals */
  MX_GPIO_Init();
  MX_CRC_Init();
  MX_DMA2D_Init();
  MX_FMC_Init();
  MX_LTDC_Init();
  MX_SPI5_Init();
  MX_TIM1_Init();
  MX_USART1_UART_Init();
  MX_I2C3_Init();
  MX_UART5_Init();
  MX_ADC1_Init();
  MX_TIM2_Init();
  MX_TouchGFX_Init();
  /* USER CODE BEGIN 2 */
  DWT_Delay_Init();
  /* USER CODE END 2 */

  /* Init scheduler */
  osKernelInitialize();  /* Call init function for freertos objects (in freertos.c) */
  MX_FREERTOS_Init();
  /* Start scheduler */
  osKernelStart();

  /* We should never get here as control is now taken by the scheduler */
  /* Infinite loop */
  while (1)
  {

  }
}

void SystemClock_Config(void)
{
  RCC_OscInitTypeDef RCC_OscInitStruct = {0};
  RCC_ClkInitTypeDef RCC_ClkInitStruct = {0};
  RCC_PeriphCLKInitTypeDef PeriphClkInitStruct = {0};

  /** Configure the main internal regulator output voltage
  */
  __HAL_RCC_PWR_CLK_ENABLE();
  __HAL_PWR_VOLTAGESCALING_CONFIG(PWR_REGULATOR_VOLTAGE_SCALE3);
  /** Initializes the RCC Oscillators according to the specified parameters
  * in the RCC_OscInitTypeDef structure.
  */
  RCC_OscInitStruct.OscillatorType = RCC_OSCILLATORTYPE_HSE;
  RCC_OscInitStruct.HSEState = RCC_HSE_ON;
  RCC_OscInitStruct.PLL.PLLState = RCC_PLL_ON;
  RCC_OscInitStruct.PLL.PLLSource = RCC_PLLSOURCE_HSE;
  RCC_OscInitStruct.PLL.PLLM = 4;
  RCC_OscInitStruct.PLL.PLLN = 90;
  RCC_OscInitStruct.PLL.PLLP = RCC_PLLP_DIV2;
  RCC_OscInitStruct.PLL.PLLQ = 3;
  if (HAL_RCC_OscConfig(&RCC_OscInitStruct) != HAL_OK)
  {
    Error_Handler();
  }
  /** Activate the Over-Drive mode
  */
  if (HAL_PWREx_EnableOverDrive() != HAL_OK)
  {
    Error_Handler();
  }
  /** Initializes the CPU, AHB and APB buses clocks
  */
  RCC_ClkInitStruct.ClockType = RCC_CLOCKTYPE_HCLK|RCC_CLOCKTYPE_SYSCLK
                              |RCC_CLOCKTYPE_PCLK1|RCC_CLOCKTYPE_PCLK2;
  RCC_ClkInitStruct.SYSCLKSource = RCC_SYSCLKSOURCE_PLLCLK;
  RCC_ClkInitStruct.AHBCLKDivider = RCC_SYSCLK_DIV1;
  RCC_ClkInitStruct.APB1CLKDivider = RCC_HCLK_DIV2;
  RCC_ClkInitStruct.APB2CLKDivider = RCC_HCLK_DIV1;

  if (HAL_RCC_ClockConfig(&RCC_ClkInitStruct, FLASH_LATENCY_2) != HAL_OK)
  {
    Error_Handler();
  }
  PeriphClkInitStruct.PeriphClockSelection = RCC_PERIPHCLK_LTDC;
  PeriphClkInitStruct.PLLSAI.PLLSAIN = 56;
  PeriphClkInitStruct.PLLSAI.PLLSAIR = 7;
  PeriphClkInitStruct.PLLSAIDivR = RCC_PLLSAIDIVR_2;
  if (HAL_RCCEx_PeriphCLKConfig(&PeriphClkInitStruct) != HAL_OK)
  {
    Error_Handler();
  }
}

 /**
  * @brief  Period elapsed callback in non blocking mode
  * @note   This function is called  when TIM6 interrupt took place, inside
  * HAL_TIM_IRQHandler(). It makes a direct call to HAL_IncTick() to increment
  * a global variable "uwTick" used as application time base.
  * @param  htim : TIM handle
  * @retval None
  */
void HAL_TIM_PeriodElapsedCallback(TIM_HandleTypeDef *htim)
{
  if (htim->Instance == TIM6) {
    HAL_IncTick();
  }
}

void Error_Handler(void)
{
  __disable_irq();
  while (1)
  {
  }
}

/************************ (C) COPYRIGHT STMicroelectronics *****END OF FILE****/

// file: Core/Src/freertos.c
/* USER CODE BEGIN Header */
/**
  ******************************************************************************
  * File Name          : freertos.c
  * Description        : Code for freertos applications
  ******************************************************************************
  * @attention
  *
  * <h2><center>&copy; Copyright (c) 2022 STMicroelectronics.
  * All rights reserved.</center></h2>
  *
  * This software component is licensed by ST under Ultimate Liberty license
  * SLA0044, the "License"; You may not use this file except in compliance with
  * the License. You may obtain a copy of the License at:
  *                             www.st.com/SLA0044
  *
  ******************************************************************************
  */
/* USER CODE END Header */

#include "FreeRTOS.h"
#include "task.h"
#include "main.h"
#include "cmsis_os.h"

/* USER CODE BEGIN Includes */
#include "event.h"
#include "eventHandlerTask.h"
#include "ringbuffer.h"
#include "mqtt.h"
#include "tft_lcd.h"
#include "Wifi.h"
#include "sensor.h"
#include "event_loop.h"
/* USER CODE END Includes */

/* USER CODE BEGIN Variables */
osThreadId           touchGFXTaskHandle;
extern osThreadId    workTaskHandle;
osSemaphoreId        envSemHandle;
extern s_mqtt        mqttSubscribe;
extern s_mqtt        mqttPublish;
extern ring_buffer_t ring_buffer;
int e_flag;
/* USER CODE END Variables */
/* Definitions for defaultTask */
osThreadId_t defaultTaskHandle;
const osThreadAttr_t defaultTask_attributes = {
  .name = "defaultTask",
  .stack_size = 4096 * 4,
  .priority = (osPriority_t) osPriorityLow,
};
/* Definitions for lcdTask */
osThreadId_t lcdTaskHandle;
const osThreadAttr_t lcdTask_attributes = {
  .name = "lcdTask",
  .stack_size = 512 * 4,
  .priority = (osPriority_t) osPriorityNormal,
};
/* Definitions for eventHandlerTas */
osThreadId_t eventHandlerTasHandle;
const osThreadAttr_t eventHandlerTas_attributes = {
  .name = "eventHandlerTas",
  .stack_size = 2048 * 4,
  .priority = (osPriority_t) osPriorityHigh,
};
/* Definitions for event_loop_task */
osThreadId_t event_loop_taskHandle;
const osThreadAttr_t event_loop_task_attributes = {
  .name = "event_loop_task",
  .stack_size = 512 * 4,
  .priority = (osPriority_t) osPriorityAboveNormal,
};
/* Definitions for envQueue */
osMessageQueueId_t envQueueHandle;
const osMessageQueueAttr_t envQueue_attributes = {
  .name = "envQueue"
};
/* Definitions for updateSensorTimer */
osTimerId_t updateSensorTimerHandle;
const osTimerAttr_t updateSensorTimer_attributes = {
  .name = "updateSensorTimer"
};
/* Definitions for sensorSem */
osSemaphoreId_t sensorSemHandle;
const osSemaphoreAttr_t sensorSem_attributes = {
  .name = "sensorSem"
};
/* Definitions for eventFlag */
osEventFlagsId_t eventFlagHandle;
const osEventFlagsAttr_t eventFlag_attributes = {
  .name = "eventFlag"
};

/* USER CODE BEGIN FunctionPrototypes */
void TouchGFX_Task(void const * argument);
/* USER CODE END FunctionPrototypes */

void StartDefaultTask(void *argument);
void _TouchGFX_Task(void *argument);
void ___eventHandler(void *argument);
void _eventLoopTask(void *argument);
void CallbackUpdateSensor(void *argument);

void MX_FREERTOS_Init(void); /* (MISRA C 2004 rule 8.1) */

/* Hook prototypes */
void vApplicationIdleHook(void);
void vApplicationStackOverflowHook(xTaskHandle xTask, signed char *pcTaskName);
void vApplicationMallocFailedHook(void);

/* USER CODE BEGIN 2 */
__weak void vApplicationIdleHook( void )
{
   /* vApplicationIdleHook() will only be called if configUSE_IDLE_HOOK is set
   to 1 in FreeRTOSConfig.h. It will be called on each iteration of the idle
   task. It is essential that code added to this hook function never attempts
   to block in any way (for example, call xQueueReceive() with a block time
   specified, or call vTaskDelay()). If the application makes use of the
   vTaskDelete() API function (as this demo application does) then it is also
   important that vApplicationIdleHook() is permitted to return to its calling
   function, because it is the responsibility of the idle task to clean up
   memory allocated by the kernel to any task that has since been deleted. */
}
/* USER CODE END 2 */

/* USER CODE BEGIN 4 */
__weak void vApplicationStackOverflowHook(xTaskHandle xTask, signed char *pcTaskName)
{
   /* Run time stack overflow checking is performed if
   configCHECK_FOR_STACK_OVERFLOW is defined to 1 or 2. This hook function is
   called if a stack overflow is detected. */
}
/* USER CODE END 4 */

/* USER CODE BEGIN 5 */
__weak void vApplicationMallocFailedHook(void)
{
   /* vApplicationMallocFailedHook() will only be called if
   configUSE_MALLOC_FAILED_HOOK is set to 1 in FreeRTOSConfig.h. It is a hook
   function that will get called if a call to pvPortMalloc() fails.
   pvPortMalloc() is called internally by the kernel whenever a task, queue,
   timer or semaphore is created. It is also called by various parts of the
   demo application. If heap_1.c or heap_2.c are used, then the size of the
   heap available to pvPortMalloc() is defined by configTOTAL_HEAP_SIZE in
   FreeRTOSConfig.h, and the xPortGetFreeHeapSize() API function can be used
   to query the size of free heap space that remains (although it does not
   provide information on how the remaining heap might be fragmented). */
}
/* USER CODE END 5 */

void MX_FREERTOS_Init(void) {
  /* USER CODE BEGIN Init */
   //osPoolDef (Pool_ID_, sizeof(ENV_MSG), ENV_MSG);
   //Pool_ID = osPoolCreate(osPool(Pool_ID_));
  /* USER CODE END Init */

  /* Create the semaphores(s) */
  /* creation of sensorSem */
  sensorSemHandle = osSemaphoreNew(1, 1, &sensorSem_attributes);

  /* Create the timer(s) */
  /* creation of updateSensorTimer */
  updateSensorTimerHandle = osTimerNew(CallbackUpdateSensor, osTimerPeriodic, NULL, &updateSensorTimer_attributes);

  /* Create the queue(s) */
  /* creation of envQueue */
  envQueueHandle = osMessageQueueNew (16, sizeof(ENV_MSG), &envQueue_attributes);

  /* Create the thread(s) */
  /* creation of defaultTask */
  defaultTaskHandle = osThreadNew(StartDefaultTask, NULL, &defaultTask_attributes);

  /* creation of lcdTask */
  lcdTaskHandle = osThreadNew(_TouchGFX_Task, NULL, &lcdTask_attributes);

  /* creation of eventHandlerTas */
  eventHandlerTasHandle = osThreadNew(___eventHandler, NULL, &eventHandlerTas_attributes);

  /* creation of event_loop_task */
  event_loop_taskHandle = osThreadNew(_eventLoopTask, NULL, &event_loop_task_attributes);

  /* Create the event(s) */
  /* creation of eventFlag */
  eventFlagHandle = osEventFlagsNew(&eventFlag_attributes);

}

void StartDefaultTask(void *argument)
{
  /* USER CODE BEGIN StartDefaultTask */
	WifiInit();
  /* Infinite loop */
  for (;;)
  {
	  osDelay(1);
  }
  /* USER CODE END StartDefaultTask */
}

void _TouchGFX_Task(void *argument)
{
  /* USER CODE BEGIN _TouchGFX_Task */
  LcdDrvStart();

  TouchGFX_Task(argument);
  /* Infinite loop */
  for(;;)
  {
    osDelay(1);
  }
  /* USER CODE END _TouchGFX_Task */
}

void ___eventHandler(void *argument)
{
  /* USER CODE BEGIN ___eventHandler */
  _eventHandler(argument);
  /* Infinite loop */
  for(;;)
  {
    osDelay(1);
  }
  /* USER CODE END ___eventHandler */
}

void _eventLoopTask(void *argument)
{
  /* USER CODE BEGIN _eventLoopTask */
	eventLoopTask(argument);
  /* Infinite loop */
  for(;;)
  {
    osDelay(1);
  }
  /* USER CODE END _eventLoopTask */
}

/* CallbackUpdateSensor function */
void CallbackUpdateSensor(void *argument)
{
  /* USER CODE BEGIN CallbackUpdateSensor */
	osEventFlagsSet(eventFlagHandle, UPDATE_SENSOR_VALUE);
  /* USER CODE END CallbackUpdateSensor */
}

/************************ (C) COPYRIGHT STMicroelectronics *****END OF FILE****/
